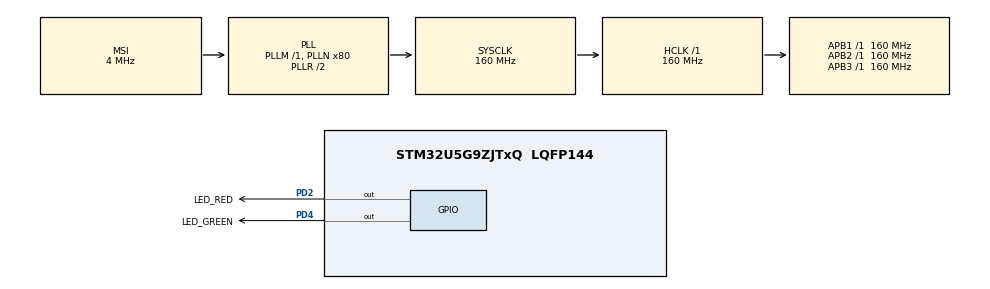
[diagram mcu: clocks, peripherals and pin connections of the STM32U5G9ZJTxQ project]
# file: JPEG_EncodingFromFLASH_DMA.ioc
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CORTEX_M33_NS.userName=CORTEX_M33
GPDMA1.DESTBURSTLENGTH_GPDMACH0=8
GPDMA1.DESTBURSTLENGTH_GPDMACH1=8
GPDMA1.DESTDATAWIDTH_GPDMACH0=DMA_DEST_DATAWIDTH_WORD
GPDMA1.DESTDATAWIDTH_GPDMACH1=DMA_DEST_DATAWIDTH_WORD
GPDMA1.DESTINC_GPDMACH0=DMA_DINC_FIXED
GPDMA1.DESTINC_GPDMACH1=DMA_DINC_INCREMENTED
GPDMA1.DIRECTION_GPDMACH0=DMA_MEMORY_TO_PERIPH
GPDMA1.IPHANDLE_GPDMACH0-SIMPLEREQUEST_GPDMACH0=__NULL
GPDMA1.IPHANDLE_GPDMACH1-SIMPLEREQUEST_GPDMACH1=__NULL
GPDMA1.PRIORITY_GPDMACH0=DMA_LOW_PRIORITY_HIGH_WEIGHT
GPDMA1.PRIORITY_GPDMACH1=DMA_LOW_PRIORITY_HIGH_WEIGHT
GPDMA1.REQUEST_GPDMACH0=GPDMA1_REQUEST_JPEG_RX
GPDMA1.REQUEST_GPDMACH1=GPDMA1_REQUEST_JPEG_TX
GPDMA1.SRCBURSTLENGTH_GPDMACH0=8
GPDMA1.SRCBURSTLENGTH_GPDMACH1=8
GPDMA1.SRCDATAWIDTH_GPDMACH0=DMA_SRC_DATAWIDTH_WORD
GPDMA1.SRCDATAWIDTH_GPDMACH1=DMA_SRC_DATAWIDTH_WORD
GPDMA1.SRCINC_GPDMACH0=DMA_SINC_INCREMENTED
GPDMA1.TRANSFERALLOCATEDPORTDEST_GPDMACH0=DMA_DEST_ALLOCATED_PORT1
GPDMA1.TRANSFERALLOCATEDPORTDEST_GPDMACH1=DMA_DEST_ALLOCATED_PORT1
JPEG.JPEG_RGB_FORMAT=JPEG_ARGB8888
JPEG.USE_JPEG_DECODER=0
Mcu.Family=STM32U5
Mcu.Name=STM32U5G9ZJTxQ
Mcu.Package=LQFP144
NVIC.GPDMA1_Channel0_IRQn=true\:6\:0\:true\:false\:true\:false\:true\:true
NVIC.GPDMA1_Channel1_IRQn=true\:7\:0\:true\:false\:true\:false\:true\:true
NVIC.JPEG_IRQn=true\:8\:0\:true\:false\:true\:true\:true\:true
NVIC.PriorityGroup=NVIC_PRIORITYGROUP_4
PD2.GPIO_Label=LED_RED
PD2.PinState=GPIO_PIN_SET
PD2.Signal=GPIO_Output
PD4.GPIO_Label=LED_GREEN
PD4.PinState=GPIO_PIN_SET
PD4.Signal=GPIO_Output
PWR.PowerMode=PWR_SMPS_SUPPLY
ProjectManager.HeapSize=0x1000
ProjectManager.StackSize=0x2000
ProjectManager.TargetToolchain=EWARM V8.50
RCC.ADCFreq_Value=16000000
RCC.AHBFreq_Value=160000000
RCC.APB1Freq_Value=160000000
RCC.APB1TimFreq_Value=160000000
RCC.APB2Freq_Value=160000000
RCC.APB2TimFreq_Value=160000000
RCC.APB3Freq_Value=160000000
RCC.CortexFreq_Value=160000000
RCC.EPOD_VALUE=4000000
RCC.HCLKFreq_Value=160000000
RCC.HSE_VALUE=16000000
RCC.HSI48_VALUE=48000000
RCC.HSI_VALUE=16000000
RCC.LSE_VALUE=32768
RCC.LSIDIV_VALUE=32000
RCC.MSI_VALUE=4000000
RCC.PLL2FRACN=0
RCC.PLL3FRACN=0
RCC.PLLFRACN=0
RCC.PLLN=80
RCC.SYSCLKFreq_VALUE=160000000
RCC.SYSCLKSource=RCC_SYSCLKSOURCE_PLLCLK
RCC.VCOOutputFreq_Value=320000000
VP_GPDMA1_VS_GPDMACH0.Mode=SIMPLEREQUEST_GPDMACH0
VP_GPDMA1_VS_GPDMACH1.Mode=SIMPLEREQUEST_GPDMACH1
VP_ICACHE_VS_ICACHE.Mode=DirectMappedCache
VP_JPEG_VS_JPEG.Mode=JPEG_Activate
VP_PWR_VS_DBSignals.Mode=DisableDeadBatterySignals
VP_PWR_VS_LPOM.Mode=PowerOptimisation
VP_PWR_VS_SECSignals.Mode=Security/Privilege
board=custom

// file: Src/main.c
/* USER CODE BEGIN Header */
/**
  ******************************************************************************
  * @file           : main.c
  * @brief          : Main program body
  ******************************************************************************
  * @attention
  *
  * Copyright (c) 2023 STMicroelectronics.
  * All rights reserved.
  *
  * This software is licensed under terms that can be found in the LICENSE file
  * in the root directory of this software component.
  * If no LICENSE file comes with this software, it is provided AS-IS.
  *
  ******************************************************************************
  */
/* USER CODE END Header */
#include "main.h"
#include "jpeg_utils_conf.h"

/* USER CODE BEGIN Includes */
#include "stm32u5g9j_discovery.h"
#include "jpeg_utils.h"
#include "encode_dma.h"
#include "image_320_240_rgb.h"
/* USER CODE END Includes */

JPEG_HandleTypeDef hjpeg;
DMA_HandleTypeDef handle_GPDMA1_Channel1;
DMA_HandleTypeDef handle_GPDMA1_Channel0;

/* USER CODE BEGIN PV */
uint32_t jpgBuffer[RGB_IMAGE_SIZE] = {0};
extern uint32_t Jpeg_HWEncodingEnd;
uint32_t RGB_ImageAddress = {0};
uint32_t tickstart;
/* USER CODE END PV */

void SystemClock_Config(void);
static void SystemPower_Config(void);
static void MX_GPDMA1_Init(void);
static void MX_GPIO_Init(void);
static void MX_ICACHE_Init(void);
static void MX_JPEG_Init(void);

int main(void)
{

  /* USER CODE BEGIN 1 */
  uint32_t jpeg_encode_processing_end = 0;

#if (JPEG_RGB_FORMAT == JPEG_ARGB8888)
  RGB_ImageAddress = (uint32_t)Image_ARGB8888;

#elif(JPEG_RGB_FORMAT == JPEG_RGB888)
  RGB_ImageAddress = (uint32_t)Image_RGB888;

#elif(JPEG_RGB_FORMAT == JPEG_RGB565)
  RGB_ImageAddress = (uint32_t)Image_RGB565;

#endif /* JPEG_RGB_FORMAT */
  /* USER CODE END 1 */

  /* MCU Configuration--------------------------------------------------------*/

  /* Reset of all peripherals, Initializes the Flash interface and the Systick. */
  HAL_Init();

  /* Configure the System Power */
  SystemPower_Config();

  /* Configure the system clock */
  SystemClock_Config();

  /* USER CODE BEGIN SysInit */
  JPEG_InitColorTables();
  /* USER CODE END SysInit */

  /* Initialize all configured peripherals */
  MX_GPDMA1_Init();
  MX_GPIO_Init();
  MX_ICACHE_Init();
  MX_JPEG_Init();
  /* USER CODE BEGIN 2 */

  /*JPEG Encoding with DMA (Not Blocking ) Method */
  JPEG_Encode_DMA(&hjpeg, RGB_ImageAddress, RGB_IMAGE_SIZE, jpgBuffer);
  /* Wait till end of JPEG encoding and perform Input/Output Processing in BackGround  */

  tickstart = HAL_GetTick();
  do
  {
    JPEG_EncodeInputHandler(&hjpeg);
    jpeg_encode_processing_end = JPEG_EncodeOutputHandler(&hjpeg);
  }while((jpeg_encode_processing_end == 0) && ((HAL_GetTick() - tickstart) < 5000));

  /* USER CODE END 2 */

  /* Infinite loop */
  while (1)
  {

    /* USER CODE BEGIN 3 */
    if (Jpeg_HWEncodingEnd != 0)
    {
      /* test ends properly */
      HAL_GPIO_WritePin(LED_GREEN_GPIO_Port, LED_GREEN_Pin, GPIO_PIN_RESET);
    }
    else
    {
      /* test error */
      HAL_GPIO_WritePin(LED_RED_GPIO_Port, LED_RED_Pin, GPIO_PIN_RESET);
    }

  }
  /* USER CODE END 3 */
}

void SystemClock_Config(void)
{
  RCC_OscInitTypeDef RCC_OscInitStruct = {0};
  RCC_ClkInitTypeDef RCC_ClkInitStruct = {0};

  /** Configure the main internal regulator output voltage
  */
  if (HAL_PWREx_ControlVoltageScaling(PWR_REGULATOR_VOLTAGE_SCALE1) != HAL_OK)
  {
    Error_Handler();
  }

  /** Initializes the CPU, AHB and APB buses clocks
  */
  RCC_OscInitStruct.OscillatorType = RCC_OSCILLATORTYPE_MSI;
  RCC_OscInitStruct.MSIState = RCC_MSI_ON;
  RCC_OscInitStruct.MSICalibrationValue = RCC_MSICALIBRATION_DEFAULT;
  RCC_OscInitStruct.MSIClockRange = RCC_MSIRANGE_4;
  RCC_OscInitStruct.PLL.PLLState = RCC_PLL_ON;
  RCC_OscInitStruct.PLL.PLLSource = RCC_PLLSOURCE_MSI;
  RCC_OscInitStruct.PLL.PLLMBOOST = RCC_PLLMBOOST_DIV1;
  RCC_OscInitStruct.PLL.PLLM = 1;
  RCC_OscInitStruct.PLL.PLLN = 80;
  RCC_OscInitStruct.PLL.PLLP = 2;
  RCC_OscInitStruct.PLL.PLLQ = 2;
  RCC_OscInitStruct.PLL.PLLR = 2;
  RCC_OscInitStruct.PLL.PLLRGE = RCC_PLLVCIRANGE_0;
  RCC_OscInitStruct.PLL.PLLFRACN = 0;
  if (HAL_RCC_OscConfig(&RCC_OscInitStruct) != HAL_OK)
  {
    Error_Handler();
  }

  /** Initializes the CPU, AHB and APB buses clocks
  */
  RCC_ClkInitStruct.ClockType = RCC_CLOCKTYPE_HCLK|RCC_CLOCKTYPE_SYSCLK
                              |RCC_CLOCKTYPE_PCLK1|RCC_CLOCKTYPE_PCLK2
                              |RCC_CLOCKTYPE_PCLK3;
  RCC_ClkInitStruct.SYSCLKSource = RCC_SYSCLKSOURCE_PLLCLK;
  RCC_ClkInitStruct.AHBCLKDivider = RCC_SYSCLK_DIV1;
  RCC_ClkInitStruct.APB1CLKDivider = RCC_HCLK_DIV1;
  RCC_ClkInitStruct.APB2CLKDivider = RCC_HCLK_DIV1;
  RCC_ClkInitStruct.APB3CLKDivider = RCC_HCLK_DIV1;

  if (HAL_RCC_ClockConfig(&RCC_ClkInitStruct, FLASH_LATENCY_4) != HAL_OK)
  {
    Error_Handler();
  }
}

/**
  * @brief Power Configuration
  * @retval None
  */
static void SystemPower_Config(void)
{

  /*
   * Disable the internal Pull-Up in Dead Battery pins of UCPD peripheral
   */
  HAL_PWREx_DisableUCPDDeadBattery();

  /*
   * Switch to SMPS regulator instead of LDO
   */
  if (HAL_PWREx_ConfigSupply(PWR_SMPS_SUPPLY) != HAL_OK)
  {
    Error_Handler();
  }
}

static void MX_GPDMA1_Init(void)
{

  /* Peripheral clock enable */
  __HAL_RCC_GPDMA1_CLK_ENABLE();

  /* GPDMA1 interrupt Init */
    HAL_NVIC_SetPriority(GPDMA1_Channel0_IRQn, 6, 0);
    HAL_NVIC_EnableIRQ(GPDMA1_Channel0_IRQn);
    HAL_NVIC_SetPriority(GPDMA1_Channel1_IRQn, 7, 0);
    HAL_NVIC_EnableIRQ(GPDMA1_Channel1_IRQn);

}

static void MX_ICACHE_Init(void)
{

  /** Enable instruction cache in 1-way (direct mapped cache)
  */
  if (HAL_ICACHE_ConfigAssociativityMode(ICACHE_1WAY) != HAL_OK)
  {
    Error_Handler();
  }
  if (HAL_ICACHE_Enable() != HAL_OK)
  {
    Error_Handler();
  }

}

static void MX_JPEG_Init(void)
{

  hjpeg.Instance = JPEG;
  if (HAL_JPEG_Init(&hjpeg) != HAL_OK)
  {
    Error_Handler();
  }

}

static void MX_GPIO_Init(void)
{
  GPIO_InitTypeDef GPIO_InitStruct = {0};

  /* GPIO Ports Clock Enable */
  __HAL_RCC_GPIOD_CLK_ENABLE();

  /*Configure GPIO pin Output Level */
  HAL_GPIO_WritePin(GPIOD, LED_RED_Pin|LED_GREEN_Pin, GPIO_PIN_SET);

  /*Configure GPIO pins : LED_RED_Pin LED_GREEN_Pin */
  GPIO_InitStruct.Pin = LED_RED_Pin|LED_GREEN_Pin;
  GPIO_InitStruct.Mode = GPIO_MODE_OUTPUT_PP;
  GPIO_InitStruct.Pull = GPIO_NOPULL;
  GPIO_InitStruct.Speed = GPIO_SPEED_FREQ_LOW;
  HAL_GPIO_Init(GPIOD, &GPIO_InitStruct);

}

/* USER CODE BEGIN 4 */
/**
  * @brief  Get the images sizes from BMP header.
  * @param  pInfo : pointer to the Info structure
  * @retval None
  */
void RGB_GetInfo(JPEG_ConfTypeDef *pInfo)
{
  /* Read Images Sizes */
  pInfo->ImageWidth         = RGB_IMAGE_WIDTH;
  pInfo->ImageHeight        = RGB_IMAGE_HEIGHT;

  /* Jpeg Encoding Setting to be set by users */
  pInfo->ChromaSubsampling  = JPEG_CHROMA_SAMPLING;
  pInfo->ColorSpace         = JPEG_COLOR_SPACE;
  pInfo->ImageQuality       = JPEG_IMAGE_QUALITY;

  /*Check if Image Sizes meets the requirements */
  if (((pInfo->ImageWidth % 8) != 0 ) || ((pInfo->ImageHeight % 8) != 0 ) || \
      (((pInfo->ImageWidth % 16) != 0 ) && (pInfo->ColorSpace == JPEG_YCBCR_COLORSPACE) && (pInfo->ChromaSubsampling != JPEG_444_SUBSAMPLING)) || \
      (((pInfo->ImageHeight % 16) != 0 ) && (pInfo->ColorSpace == JPEG_YCBCR_COLORSPACE) && (pInfo->ChromaSubsampling == JPEG_420_SUBSAMPLING)))
  {
    Error_Handler();
  }
}
/* USER CODE END 4 */

void Error_Handler(void)
{
  /* USER CODE BEGIN Error_Handler_Debug */
  /* User can add his own implementation to report the HAL error return state */
  __disable_irq();
  while (1)
  {
    HAL_GPIO_WritePin(LED_RED_GPIO_Port, LED_RED_Pin, GPIO_PIN_RESET);
  }
  /* USER CODE END Error_Handler_Debug */
}
